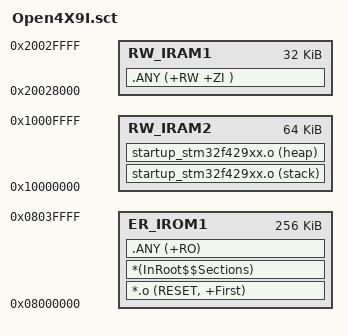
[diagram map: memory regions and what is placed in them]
; *************************************************************
; *** Scatter-Loading Description File generated by uVision ***
; *************************************************************

LR_IROM1 0x08000000 0x00040000  {    ; load region size_region
  ER_IROM1 0x08000000 0x00040000  {  ; load address = execution address
   *.o (RESET, +First)
   *(InRoot$$Sections)
   .ANY (+RO)
  }
  RW_IRAM1 0x20028000 0x00008000  {  ; RW data
   .ANY (+RW +ZI )
  }
  RW_IRAM2 0x10000000 0x00010000  {
   startup_stm32f429xx.o (stack)
   startup_stm32f429xx.o (heap)
	
  }
	;ER_IROM2 0x900C0000 0x00020000  {    ; load region size_region
	 ; screen.o (+RO)
	;  	  
  ;}
}



